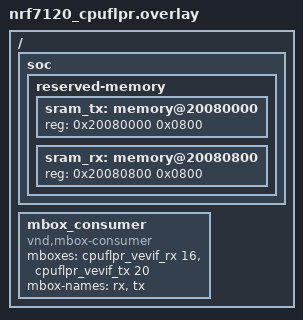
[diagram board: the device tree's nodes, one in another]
/*
 * Copyright (c) 2026 Nordic Semiconductor ASA
 *
 * SPDX-License-Identifier: LicenseRef-Nordic-5-Clause
 */

/ {
	soc {
		reserved-memory {
			#address-cells = <1>;
			#size-cells = <1>;

			sram_tx: memory@20080000 {
				reg = <0x20080000 0x0800>;
			};

			sram_rx: memory@20080800 {
				reg = <0x20080800 0x0800>;
			};
		};
	};

	mbox_consumer: mbox_consumer {
		compatible = "vnd,mbox-consumer";
		mboxes = <&cpuflpr_vevif_rx 16>, <&cpuflpr_vevif_tx 20>;
		mbox-names = "rx", "tx";
	};
};
